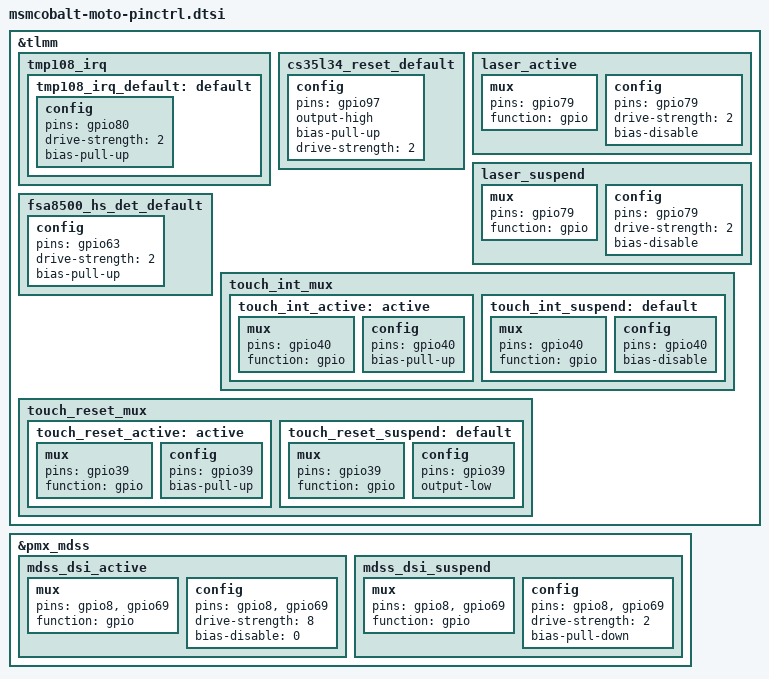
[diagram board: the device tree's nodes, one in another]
/* Copyright (c) 2016, Motorola Mobility Inc. All rights reserved.
 *
 * This program is free software; you can redistribute it and/or modify
 * it under the terms of the GNU General Public License version 2 and
 * only version 2 as published by the Free Software Foundation.
 *
 * This program is distributed in the hope that it will be useful,
 * but WITHOUT ANY WARRANTY; without even the implied warranty of
 * MERCHANTABILITY or FITNESS FOR A PARTICULAR PURPOSE.  See the
 * GNU General Public License for more details.
 */

&tlmm {

        tmp108_irq {
                tmp108_irq_default: default {
                        config {
                                pins = "gpio80";
                                drive-strength = <2>;
                                bias-pull-up;
                        };
                };
        };

        cs35l34_reset_default: cs35l34_reset_default {
                config {
                        pins = "gpio97";
                        output-high;
                        bias-pull-up;
                        drive-strength = <2>;
                };
        };

	laser_active: laser_active {
		mux {
			pins = "gpio79";
			function = "gpio";
		};

		config {
			pins = "gpio79";
			drive-strength = <2>;
			bias-disable; /* No PULL */
		};
	};

	laser_suspend: laser_suspend {
		mux {
			pins = "gpio79";
			function = "gpio";
		};

		config {
			pins = "gpio79";
			drive-strength = <2>;
			bias-disable; /* No PULL */
		};
	};

	fsa8500_hs_det_default: fsa8500_hs_det_default {
		config {
			pins = "gpio63";
			drive-strength = <2>;
			bias-pull-up;
		};
	};

	touch_int_mux {
		touch_int_active: active {
			mux {
				pins = "gpio40";
				function = "gpio";
			};
			config {
				pins = "gpio40";
				bias-pull-up;
			};
		};

		touch_int_suspend: default {
			mux {
				pins = "gpio40";
				function = "gpio";
			};
			config {
				pins = "gpio40";
				bias-disable;
			};
		};
	};

	touch_reset_mux {
		touch_reset_active: active {
			mux {
				pins = "gpio39";
				function = "gpio";
			};
			config {
				pins = "gpio39";
				bias-pull-up;
			};
		};

		touch_reset_suspend: default {
			mux {
				pins = "gpio39";
				function = "gpio";
			};
			config {
				pins = "gpio39";
				output-low;
			};
		};
	};
};

&pmx_mdss{
	mdss_dsi_active: mdss_dsi_active {
		mux {
			pins = "gpio8", "gpio69";
			function = "gpio";
		};

		config {
			pins = "gpio8", "gpio69";
			drive-strength = <8>; /* 8 mA */
			bias-disable = <0>; /* no pull */
		};
	};

	mdss_dsi_suspend: mdss_dsi_suspend {
		mux {
			pins = "gpio8", "gpio69";
			function = "gpio";
		};

		config {
			pins = "gpio8", "gpio69";
			drive-strength = <2>; /* 2 mA */
			bias-pull-down; /* pull down */
		};
	};
};
